# AM335x register map
Vendor: Texas Instruments; Series: Sitara AM335x; File version: 1.1
CPU: Cortex-A8 r0p0, little endian
Registers are 32-bit, read-write, reset 0x0 unless marked. A register's access mark holds for its fields unless they carry their own. Offsets are from the block's base; [hi:lo] are bit positions; 'fields as' and 'values as' point back to an identical list.

## PRM_DEVICE — Power Reset Module - Device
Base 0x44E00F00
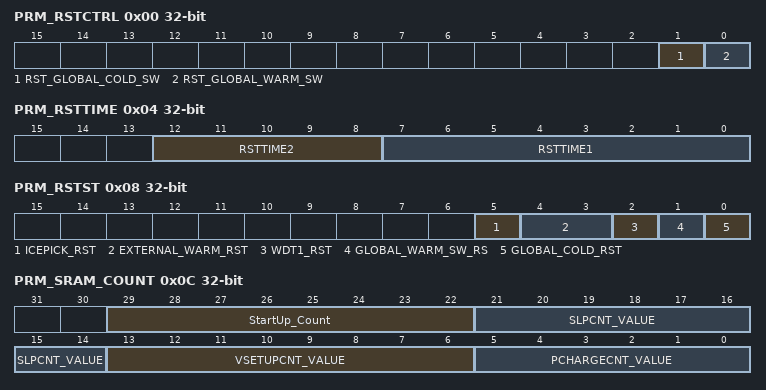
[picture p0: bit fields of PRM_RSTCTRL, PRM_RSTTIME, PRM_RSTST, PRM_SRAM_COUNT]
0x00 PRM_RSTCTRL
  [1] RST_GLOBAL_COLD_SW — bit: 1 (W) Global COLD software reset control. [0x0 = Global warm software reset is cleared.; 0x1 = Asserts a global warm software reset.]
  [0] RST_GLOBAL_WARM_SW — bit: 0 (W) Global WARM software reset control. [0x0 = Global COLD; 0x1 = Asserts a global COLD software reset.]
0x04 PRM_RSTTIME
  [12:8] RSTTIME2 — (Global) reset duration 1 (number of CLK_M_OSC clock cycles)
  [7:0] RSTTIME1 — (Power domain) reset duration 2 (number of CLK_M_OSC clockcycles)
0x08 PRM_RSTST
  [5] ICEPICK_RST — bit: 9 (RW) IcePick reset event. [0x0 = No ICEPICK reset.; 0x1 = IcePick reset has occurred.]
  [4:3] EXTERNAL_WARM_RST — bit: 5 (RW) External warm reset event [warm reset insensitive] [0x0 = No global warm reset.; 0x1 = Global external warm reset has occurred.]
  [2] WDT1_RST — bit: 4 (RW) Watchdog1 timer reset event. [0x0 = No watchdog reset.; 0x1 = watchdog reset has occurred.]
  [1] GLOBAL_WARM_SW_RS — bit: 1 (RW) Global warm software reset event [warm reset insensitive] [0x0 = No global warm SW reset; 0x1 = Global warm SW reset has occurred.]
  [0] GLOBAL_COLD_RST — bit: 0 (RW) Power-on (cold) reset event [warm reset insensitive] [0x0 = No power-on reset.; 0x1 = Power-on reset has occurred.]
0x0C PRM_SRAM_COUNT
  [29:22] StartUp_Count — bit: 24.31 (RW) Determines the start-up duration of SRAM and ABB LDO.The duration is computed as 16 x NbCycles of system clock cycles.Target is 50us.
  [21:14] SLPCNT_VALUE — Delay between retention/off assertion of last SRAM bank and SRAMALLRET signal to LDO is driven high. Counting on system clock.Target is 2us.
  [13:6] VSETUPCNT_VALUE — SRAM LDO rampup time from retention to active mode.The duration is computed as 8 x NbCycles of system clock cycles.Target is 30us.
  [5:0] PCHARGECNT_VALUE — Delay between de-assertion of standby_rta_ret_on and standby_rta_ret_good. Counting on system clock.Target is 600ns.
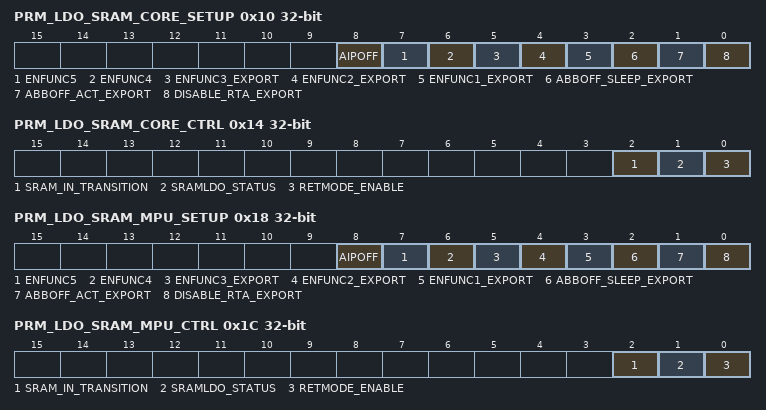
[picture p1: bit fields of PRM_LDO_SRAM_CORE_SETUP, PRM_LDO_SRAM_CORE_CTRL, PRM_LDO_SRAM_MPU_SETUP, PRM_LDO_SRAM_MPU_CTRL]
0x10 PRM_LDO_SRAM_CORE_SETUP
  [8] AIPOFF — bit: 8 (RW) Override on AIPOFF input of SRAM LDO. [0x0 = AIPOFF signal is not overriden; 0x1 = AIPOFF signal is overriden to '1'.]
  [7] ENFUNC5 — bit: 7 (RW) ENFUNC5 input of SRAM LDO. [0x0 = One_step; 0x1 = Two_step]
  [6] ENFUNC4 — bit: 6 (RW) ENFUNC4 input of SRAM LDO. [0x0 = Ext_clock; 0x1 = No_ext_clock]
  [5] ENFUNC3_EXPORT — bit: 5 (RW) ENFUNC3 input of SRAM LDO. [0x0 = Sub_regul_disabled; 0x1 = Sub_regul_enabled]
  [4] ENFUNC2_EXPORT — bit: 4 (RW) ENFUNC2 input of SRAM LDO. [0x0 = Ext_cap; 0x1 = No_ext_cap]
  [3] ENFUNC1_EXPORT — bit: 3 (RW) ENFUNC1 input of SRAM LDO. [0x0 = Short_prot_disabled; 0x1 = Short_prot_enabled]
  [2] ABBOFF_SLEEP_EXPORT — bit: 2 (RW) Determines whether SRAMNWA is supplied by VDDS or VDDAR during deep-sleep. [0x0 = SRAMNWA supplied with VDDS; 0x1 = SRAMNW_ACT_VDDASRAMNWA supplied with VDDAR]
  [1] ABBOFF_ACT_EXPORT — bit: 1 (RW) Determines whether SRAMNWA is supplied by VDDS or VDDAR during active mode. [0x0 = SRAMNWA supplied with VDDS; 0x1 = SRAMNW_ACT_VDDASRAMNWA supplied with VDDAR]
  [0] DISABLE_RTA_EXPORT — bit: 0 (RW) Control for HD memory RTA feature. [0x0 = RTA_ENABLED; 0x1 = RTA_DISABLED]
0x14 PRM_LDO_SRAM_CORE_CTRL
  [2] SRAM_IN_TRANSITION — bit: 9 (R) Status indicating SRAM LDO state machine state. [0x0 = IDLE; 0x1 = IN_TRANSITION]
  [1] SRAMLDO_STATUS — bit: 8 (R) SRAMLDO status [0x0 = ACTIVE; 0x1 = RETENTION]
  [0] RETMODE_ENABLE — bit: 0 (RW) Control if the SRAM LDO retention mode is used or not. [0x0 = Disabled; 0x1 = Enabled]
0x18 PRM_LDO_SRAM_MPU_SETUP
  fields as PRM_LDO_SRAM_CORE_SETUP
0x1C PRM_LDO_SRAM_MPU_CTRL
  fields as PRM_LDO_SRAM_CORE_CTRL
